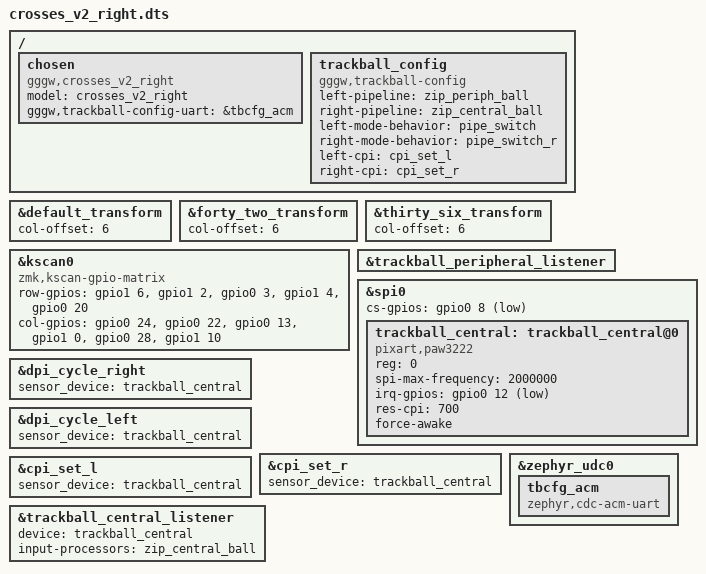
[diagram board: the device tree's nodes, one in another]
/*
 * Copyright (c) 2026 Vincent Franco
 * SPDX-License-Identifier: MIT
 */

#include "crosses_v2.dts"
#include <zephyr/dt-bindings/input/input-event-codes.h>
#include <input/processors.dtsi>

/ {
  chosen {
    model = "crosses_v2_right";
    compatible = "gggw,crosses_v2_right";
  };
};

// Offset right side
&default_transform {
  col-offset = <6>;
};

&forty_two_transform {
  col-offset = <6>;
};

&thirty_six_transform {
  col-offset = <6>;
};

&kscan0 {
  compatible = "zmk,kscan-gpio-matrix";

  row-gpios
    = <&gpio1 6 (GPIO_ACTIVE_HIGH | GPIO_PULL_DOWN)>
    , <&gpio1 2 (GPIO_ACTIVE_HIGH | GPIO_PULL_DOWN)>
    , <&gpio0 3 (GPIO_ACTIVE_HIGH | GPIO_PULL_DOWN)>
    , <&gpio1 4 (GPIO_ACTIVE_HIGH | GPIO_PULL_DOWN)>
    , <&gpio0 20 (GPIO_ACTIVE_HIGH | GPIO_PULL_DOWN)>
    ;

  col-gpios
    = <&gpio0 24 GPIO_ACTIVE_HIGH>
    , <&gpio0 22 GPIO_ACTIVE_HIGH>
    , <&gpio0 13 GPIO_ACTIVE_HIGH>
    , <&gpio1 0 GPIO_ACTIVE_HIGH>
    , <&gpio0 28 GPIO_ACTIVE_HIGH>
    , <&gpio1 10 GPIO_ACTIVE_HIGH>
    ;
};

&trackball_peripheral_listener {
    status = "okay";
};

&spi0 {
    cs-gpios = <&gpio0 8 GPIO_ACTIVE_LOW>;

    trackball_central: trackball_central@0 {
        status = "okay";
        compatible = "pixart,paw3222";
        reg = <0>;
        spi-max-frequency = <2000000>;
        irq-gpios = <&gpio0 12 GPIO_ACTIVE_LOW>;
        res-cpi = <700>;
        force-awake;
    };
};

&dpi_cycle_right {
    sensor_device = <&trackball_central>;
};

// Never invoked on this half (EVENT_SOURCE locality runs it on the left
// half); points at the local sensor only to satisfy the required phandle.
&dpi_cycle_left {
    sensor_device = <&trackball_central>;
};

// Right CPI set targets the local central sensor. cpi_set_l is a placeholder
// on this half: the central relays left-ball CPI to the peripheral (source 0)
// rather than invoking cpi_set_l locally.
&cpi_set_r {
    sensor_device = <&trackball_central>;
};

&cpi_set_l {
    sensor_device = <&trackball_central>;
};

// Central-only: the host-facing config service (GATT). Lives on the central
// because that is the host's single connection point; it relays to the left
// ball and keeps the authoritative state mirror.
/ {
    trackball_config {
        compatible = "gggw,trackball-config";
        left-pipeline = <&zip_periph_ball>;
        right-pipeline = <&zip_central_ball>;
        left-mode-behavior = <&pipe_switch>;
        right-mode-behavior = <&pipe_switch_r>;
        left-cpi = <&cpi_set_l>;
        right-cpi = <&cpi_set_r>;
    };
};

// Central-only: a dedicated USB CDC-ACM serial port for the host config web app
// (Web Serial), separate from ZMK Studio's RPC port. See
// zmk-trackball-config/docs/adr/0004.
&zephyr_udc0 {
    tbcfg_acm: tbcfg_acm {
        compatible = "zephyr,cdc-acm-uart";
    };
};

/ {
    chosen {
        gggw,trackball-config-uart = &tbcfg_acm;
    };
};

// Overrides for the input listener node
// The X/Y invert that used to live here now lives inside zip_central_ball's
// "mouse"/Cursor pipeline; the switch lets the right ball select modes too.
&trackball_central_listener {
    status = "okay";
    device = <&trackball_central>;
    input-processors = <&zip_central_ball>;
};
